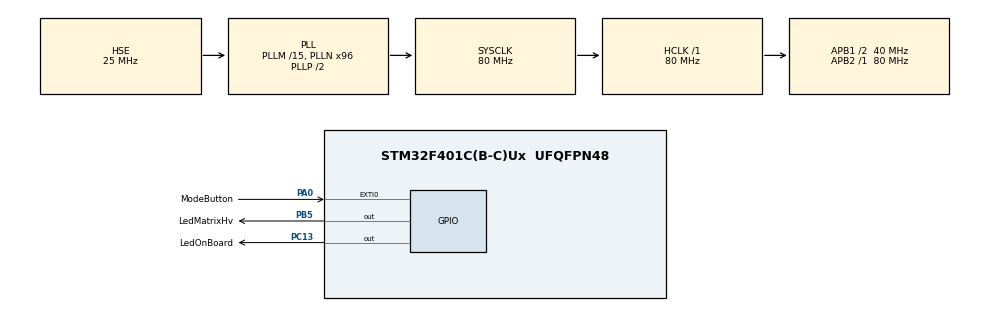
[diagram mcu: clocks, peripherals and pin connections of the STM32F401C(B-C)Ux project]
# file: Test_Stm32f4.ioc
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Mcu.Family=STM32F4
Mcu.Name=STM32F401C(B-C)Ux
Mcu.Package=UFQFPN48
NVIC.EXTI0_IRQn=true\:0\:0\:false\:false\:true\:true\:true\:true
NVIC.PriorityGroup=NVIC_PRIORITYGROUP_4
PA0-WKUP.GPIO_Label=ModeButton
PA0-WKUP.GPIO_ModeDefaultEXTI=GPIO_MODE_IT_FALLING
PA0-WKUP.GPIO_PuPd=GPIO_PULLUP
PA0-WKUP.Signal=GPXTI0
PA13.Mode=Serial_Wire
PA13.Signal=SYS_JTMS-SWDIO
PA14.Mode=Serial_Wire
PA14.Signal=SYS_JTCK-SWCLK
PB5.GPIO_Label=LedMatrixHv
PB5.GPIO_Speed=GPIO_SPEED_FREQ_VERY_HIGH
PB5.PinState=GPIO_PIN_RESET
PB5.Signal=GPIO_Output
PC13-ANTI_TAMP.GPIO_Label=LedOnBoard
PC13-ANTI_TAMP.PinState=GPIO_PIN_SET
PC13-ANTI_TAMP.Signal=GPIO_Output
PC14-OSC32_IN.Mode=LSE-External-Oscillator
PC14-OSC32_IN.Signal=RCC_OSC32_IN
PC15-OSC32_OUT.Mode=LSE-External-Oscillator
PC15-OSC32_OUT.Signal=RCC_OSC32_OUT
PH0\ -\ OSC_IN.Mode=HSE-External-Oscillator
PH0\ -\ OSC_IN.Signal=RCC_OSC_IN
PH1\ -\ OSC_OUT.Mode=HSE-External-Oscillator
PH1\ -\ OSC_OUT.Signal=RCC_OSC_OUT
ProjectManager.HeapSize=0x200
ProjectManager.StackSize=0x400
ProjectManager.TargetToolchain=MDK-ARM V5.32
RCC.48MHZClocksFreq_Value=32000000
RCC.AHBFreq_Value=80000000
RCC.APB1CLKDivider=RCC_HCLK_DIV2
RCC.APB1Freq_Value=40000000
RCC.APB1TimFreq_Value=80000000
RCC.APB2Freq_Value=80000000
RCC.APB2TimFreq_Value=80000000
RCC.CortexFreq_Value=10000000
RCC.Cortex_Div=SYSTICK_CLKSOURCE_HCLK_DIV8
RCC.HCLKFreq_Value=80000000
RCC.HSE_VALUE=25000000
RCC.HSI_VALUE=16000000
RCC.PLLM=15
RCC.PLLN=96
RCC.PLLQ=5
RCC.PLLSourceVirtual=RCC_PLLSOURCE_HSE
RCC.SYSCLKFreq_VALUE=80000000
RCC.SYSCLKSource=RCC_SYSCLKSOURCE_PLLCLK
RCC.VCOOutputFreq_Value=160000000
board=custom

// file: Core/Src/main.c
/* USER CODE BEGIN Header */
/**
  ******************************************************************************
  * @file           : main.c
  * @brief          : Main program body
  ******************************************************************************
  * @attention
  *
  * Copyright (c) 2025 STMicroelectronics.
  * All rights reserved.
  *
  * This software is licensed under terms that can be found in the LICENSE file
  * in the root directory of this software component.
  * If no LICENSE file comes with this software, it is provided AS-IS.
  *
  ******************************************************************************
  */
/* USER CODE END Header */
#include "main.h"

/* USER CODE BEGIN Includes */
#include "Mpu_If.h"
#include "WS2812b_If.h"
/* USER CODE END Includes */

/* USER CODE BEGIN PV */
static uint8_t u1a_App_Mode;
/* USER CODE END PV */

void SystemClock_Config(void);
static void MX_GPIO_Init(void);

int main(void)
{

  /* USER CODE BEGIN 1 */
  u1a_App_Mode = 0U;
  /* USER CODE END 1 */

  /* MCU Configuration--------------------------------------------------------*/

  /* Reset of all peripherals, Initializes the Flash interface and the Systick. */
  HAL_Init();

  /* Configure the system clock */
  SystemClock_Config();

  /* USER CODE BEGIN SysInit */
  // f_Mpu_Init();
  /* USER CODE END SysInit */

  /* Initialize all configured peripherals */
  MX_GPIO_Init();
  /* USER CODE BEGIN 2 */
  f_WS2812b_Init();
  HAL_Delay(1000);
  /* USER CODE END 2 */

  /* Infinite loop */
  /* USER CODE BEGIN WHILE */

  while (1)
  {
    /* Mode */
    switch ( u1a_App_Mode )
    {
      case 0U:
        f_WS2812b_LedEffect3();
        HAL_Delay( 1000UL );
        break;
    case 1U:
      f_WS2812b_LedEffect1();
      HAL_Delay( 100UL );
      break;
      case 2U:
      /* Run this mode one time */
      f_WS2812b_LedEffect2();
      HAL_Delay( 1000UL );
      break;
    case 0xFFU:
      /* Idle */
      HAL_Delay( 500UL );
      break;
    default:
      /* Do nothing */
      break;
    }
    /* USER CODE END WHILE */

  }
}

void SystemClock_Config(void)
{
  RCC_OscInitTypeDef RCC_OscInitStruct = {0};
  RCC_ClkInitTypeDef RCC_ClkInitStruct = {0};

  /** Configure the main internal regulator output voltage
  */
  __HAL_RCC_PWR_CLK_ENABLE();
  __HAL_PWR_VOLTAGESCALING_CONFIG(PWR_REGULATOR_VOLTAGE_SCALE2);

  /** Initializes the RCC Oscillators according to the specified parameters
  * in the RCC_OscInitTypeDef structure.
  */
  RCC_OscInitStruct.OscillatorType = RCC_OSCILLATORTYPE_HSE;
  RCC_OscInitStruct.HSEState = RCC_HSE_ON;
  RCC_OscInitStruct.PLL.PLLState = RCC_PLL_ON;
  RCC_OscInitStruct.PLL.PLLSource = RCC_PLLSOURCE_HSE;
  RCC_OscInitStruct.PLL.PLLM = 15;
  RCC_OscInitStruct.PLL.PLLN = 96;
  RCC_OscInitStruct.PLL.PLLP = RCC_PLLP_DIV2;
  RCC_OscInitStruct.PLL.PLLQ = 5;
  if (HAL_RCC_OscConfig(&RCC_OscInitStruct) != HAL_OK)
  {
    Error_Handler();
  }

  /** Initializes the CPU, AHB and APB buses clocks
  */
  RCC_ClkInitStruct.ClockType = RCC_CLOCKTYPE_HCLK|RCC_CLOCKTYPE_SYSCLK
                              |RCC_CLOCKTYPE_PCLK1|RCC_CLOCKTYPE_PCLK2;
  RCC_ClkInitStruct.SYSCLKSource = RCC_SYSCLKSOURCE_PLLCLK;
  RCC_ClkInitStruct.AHBCLKDivider = RCC_SYSCLK_DIV1;
  RCC_ClkInitStruct.APB1CLKDivider = RCC_HCLK_DIV2;
  RCC_ClkInitStruct.APB2CLKDivider = RCC_HCLK_DIV1;

  if (HAL_RCC_ClockConfig(&RCC_ClkInitStruct, FLASH_LATENCY_2) != HAL_OK)
  {
    Error_Handler();
  }
}

static void MX_GPIO_Init(void)
{
  GPIO_InitTypeDef GPIO_InitStruct = {0};

  /* GPIO Ports Clock Enable */
  __HAL_RCC_GPIOC_CLK_ENABLE();
  __HAL_RCC_GPIOH_CLK_ENABLE();
  __HAL_RCC_GPIOA_CLK_ENABLE();
  __HAL_RCC_GPIOB_CLK_ENABLE();

  /*Configure GPIO pin Output Level */
  HAL_GPIO_WritePin(LedOnBoard_GPIO_Port, LedOnBoard_Pin, GPIO_PIN_SET);

  /*Configure GPIO pin Output Level */
  HAL_GPIO_WritePin(LedMatrixHv_GPIO_Port, LedMatrixHv_Pin, GPIO_PIN_RESET);

  /*Configure GPIO pin : LedOnBoard_Pin */
  GPIO_InitStruct.Pin = LedOnBoard_Pin;
  GPIO_InitStruct.Mode = GPIO_MODE_OUTPUT_PP;
  GPIO_InitStruct.Pull = GPIO_NOPULL;
  GPIO_InitStruct.Speed = GPIO_SPEED_FREQ_LOW;
  HAL_GPIO_Init(LedOnBoard_GPIO_Port, &GPIO_InitStruct);

  /*Configure GPIO pin : ModeButton_Pin */
  GPIO_InitStruct.Pin = ModeButton_Pin;
  GPIO_InitStruct.Mode = GPIO_MODE_IT_FALLING;
  GPIO_InitStruct.Pull = GPIO_PULLUP;
  HAL_GPIO_Init(ModeButton_GPIO_Port, &GPIO_InitStruct);

  /*Configure GPIO pin : LedMatrixHv_Pin */
  GPIO_InitStruct.Pin = LedMatrixHv_Pin;
  GPIO_InitStruct.Mode = GPIO_MODE_OUTPUT_PP;
  GPIO_InitStruct.Pull = GPIO_NOPULL;
  GPIO_InitStruct.Speed = GPIO_SPEED_FREQ_VERY_HIGH;
  HAL_GPIO_Init(LedMatrixHv_GPIO_Port, &GPIO_InitStruct);

  /* EXTI interrupt init*/
  HAL_NVIC_SetPriority(EXTI0_IRQn, 0, 0);
  HAL_NVIC_EnableIRQ(EXTI0_IRQn);

}

/* USER CODE BEGIN 4 */
void HAL_GPIO_EXTI_Callback(uint16_t GPIO_Pin)
{
  /* USER CODE BEGIN HAL_GPIO_EXTI_Callback 0 */
  if ( GPIO_Pin == ModeButton_Pin )
  {
    /* Change mode */
    u1a_App_Mode++;
    if ( u1a_App_Mode > 2U )
    {
      u1a_App_Mode = 0U;
    }
  }
  /* USER CODE END HAL_GPIO_EXTI_Callback 0 */

  /* USER CODE BEGIN HAL_GPIO_EXTI_Callback 1 */

  /* USER CODE END HAL_GPIO_EXTI_Callback 1 */
}
/* USER CODE END 4 */

void Error_Handler(void)
{
  __disable_irq();
  while (1)
  {
  }
}
